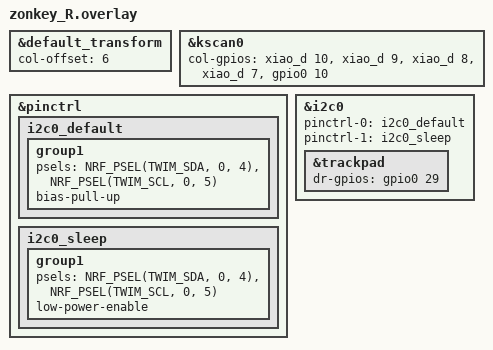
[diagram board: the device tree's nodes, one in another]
#include "zonkey.dtsi"

&default_transform {
    col-offset = <6>;
};

&kscan0 {
    col-gpios
        = <&xiao_d 10 GPIO_ACTIVE_HIGH>
        , <&xiao_d 9 GPIO_ACTIVE_HIGH> 
        , <&xiao_d 8 GPIO_ACTIVE_HIGH> 
        , <&xiao_d 7 GPIO_ACTIVE_HIGH> 
        , <&gpio0 10 GPIO_ACTIVE_HIGH>
        ;
};

/* I2Cピンの設定（D4, D5） */
&pinctrl {
    i2c0_default: i2c0_default {
        group1 {
            psels = <NRF_PSEL(TWIM_SDA, 0, 4)>, 
                    <NRF_PSEL(TWIM_SCL, 0, 5)>; 
            bias-pull-up;
        };
    };

    i2c0_sleep: i2c0_sleep {
        group1 {
            psels = <NRF_PSEL(TWIM_SDA, 0, 4)>,
                    <NRF_PSEL(TWIM_SCL, 0, 5)>;
            low-power-enable;
        };
    };
};

/* トラックパッドの具体的な設定（dtsiの内容を補足） */
&i2c0 {
    status = "okay";
    pinctrl-0 = <&i2c0_default>;
    pinctrl-1 = <&i2c0_sleep>;
    pinctrl-names = "default", "sleep";

    /* 重複していた trackpad 定義を &trackpad への参照にまとめました */
    &trackpad {
        /* 配線に合わせて D3(P0.29) を指定 */
        dr-gpios = <&gpio0 29 (GPIO_ACTIVE_HIGH)>; 
        /* dtsi側で sensitivity = "1x"; と書いているので
           ここでは書かなくてOKです 
        */
    };
};
